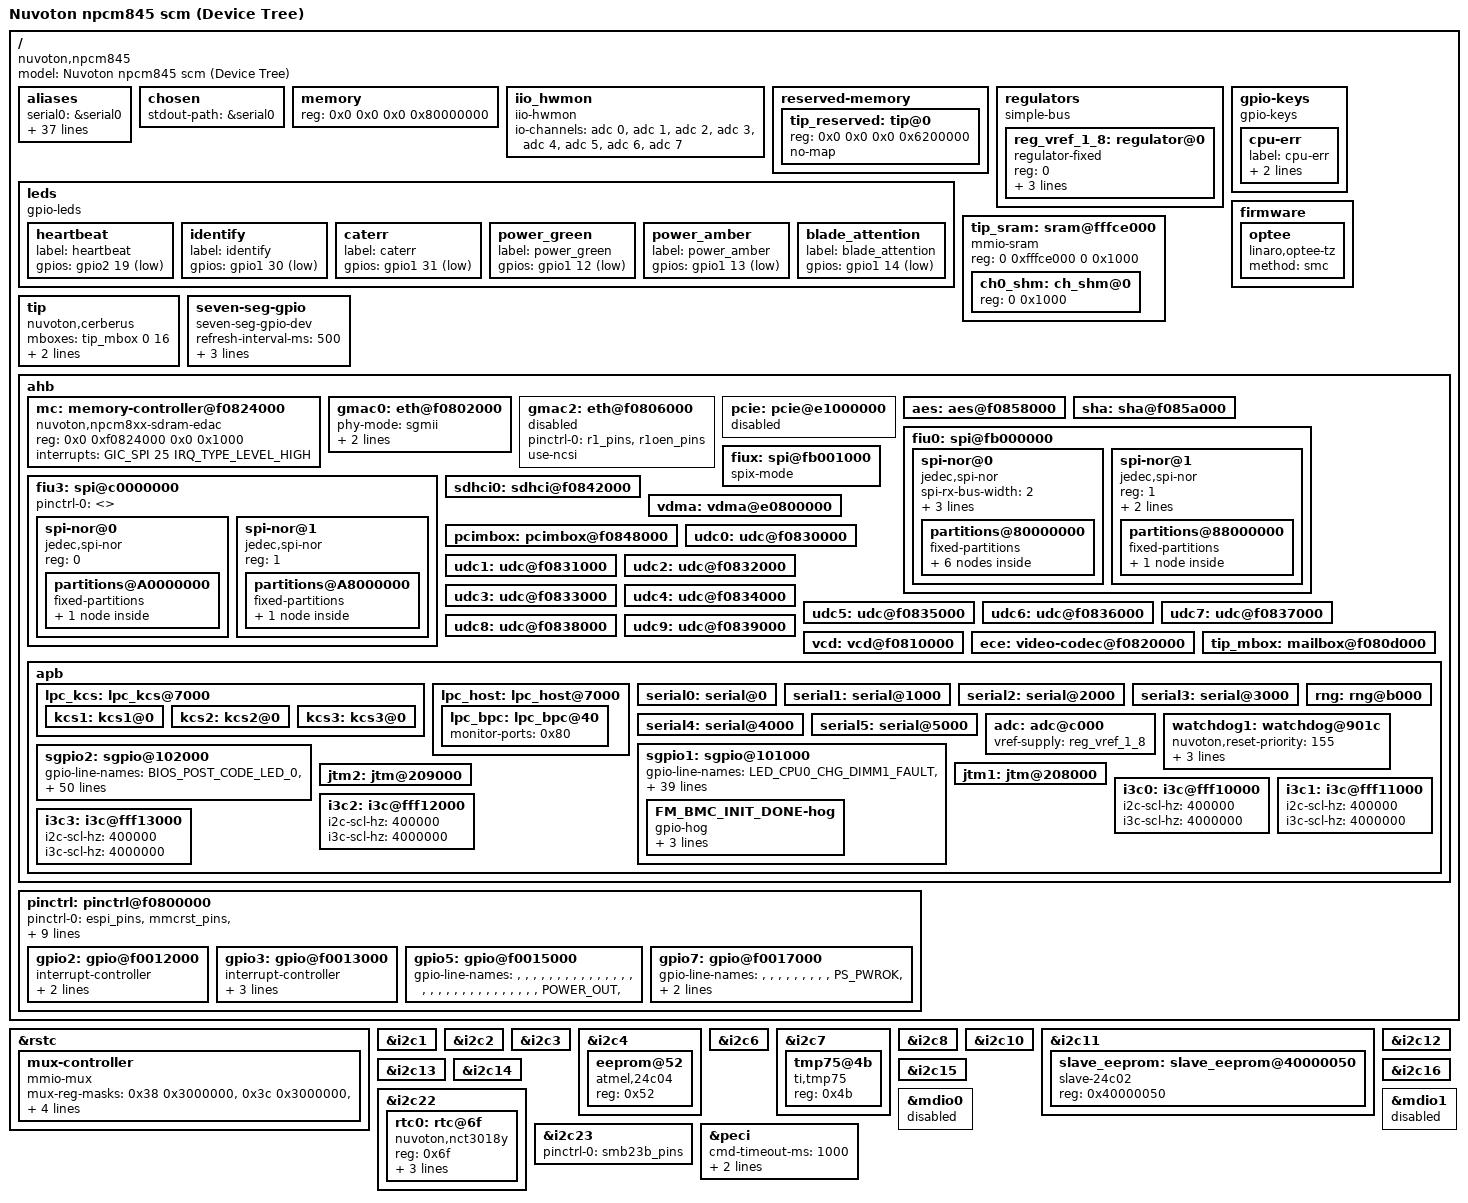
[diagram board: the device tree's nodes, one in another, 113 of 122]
// SPDX-License-Identifier: GPL-2.0
// Copyright (c) 2018 Nuvoton Technology tomer.maimon@nuvoton.com
// Copyright 2018 Google, Inc.

/dts-v1/;
#include "nuvoton-npcm845.dtsi"
#include "nuvoton-npcm845-pincfg-evb.dtsi"
#include <dt-bindings/thermal/thermal.h>

/ {
	model = "Nuvoton npcm845 scm (Device Tree)";
	compatible = "nuvoton,npcm845";

	aliases {
		serial0 = &serial0;
		serial1 = &serial1;
		serial2 = &serial2;
		serial3 = &serial3;
		serial4 = &serial4;
		serial5 = &serial5;
		ethernet0 = &gmac0;
		ethernet1 = &gmac2;
		udc0 = &udc0;
		udc1 = &udc1;
		udc2 = &udc2;
		udc3 = &udc3;
		udc4 = &udc4;
		udc5 = &udc5;
		udc6 = &udc6;
		udc7 = &udc7;
		udc8 = &udc8;
		udc9 = &udc9;
		i2c1 = &i2c1;
		i2c2 = &i2c2;
		i2c3 = &i2c3;
		i2c4 = &i2c4;
		i2c6 = &i2c6;
		i2c7 = &i2c7;
		i2c8 = &i2c8;
		i2c10 = &i2c10;
		i2c12 = &i2c12;
		i2c13 = &i2c13;
		i2c14 = &i2c14;
		i2c15 = &i2c15;
		i2c16 = &i2c23;
		i2c17 = &i2c11;
		i2c22 = &i2c22;
		i2c23 = &i2c16;
		fiu0 = &fiu0;
		fiu1 = &fiu3;
		fiu2 = &fiux;
		fiu3 = &fiu1;
	};

	chosen {
		stdout-path = &serial0;
	};

	memory {
		reg = <0x0 0x0 0x0 0x80000000>;
	};

	iio_hwmon {
		compatible = "iio-hwmon";
		io-channels = <&adc 0>, <&adc 1>, <&adc 2>, <&adc 3>,
			<&adc 4>, <&adc 5>, <&adc 6>, <&adc 7>;
	};

	reserved-memory {
		#address-cells = <2>;
		#size-cells = <2>;
		ranges;

		tip_reserved: tip@0 {
			reg = <0x0 0x0 0x0 0x6200000>;
			no-map;
		};
	};

	regulators {
		compatible = "simple-bus";
		#address-cells = <1>;
		#size-cells = <0>;

		reg_vref_1_8: regulator@0 {
			compatible = "regulator-fixed";
			reg = <0>;
			regulator-name = "vref_1_8v";
			regulator-min-microvolt = <1800000>;
			regulator-max-microvolt = <1800000>;
		};
	};

	leds {
		compatible = "gpio-leds";

		heartbeat {
			label = "heartbeat";
			gpios = <&gpio2 19 GPIO_ACTIVE_LOW>; /* gpio83 */
		};

		identify {
			label = "identify";
			gpios = <&gpio1 30 GPIO_ACTIVE_LOW>; /* gpio62 */
		};

		caterr {
			label = "caterr";
			gpios = <&gpio1 31 GPIO_ACTIVE_LOW>; /* gpio63 */
		};

		power_green {
			label = "power_green";
			gpios = <&gpio1 12 GPIO_ACTIVE_LOW>; /* gpio44 */
		};

		power_amber {
			label = "power_amber";
			gpios = <&gpio1 13 GPIO_ACTIVE_LOW>; /* gpio45 */
		};

		blade_attention {
			label = "blade_attention";
			gpios = <&gpio1 14 GPIO_ACTIVE_LOW>; /* gpio46 */
		};
	};

	gpio-keys {
		compatible = "gpio-keys";
		cpu-err {
			label = "cpu-err";
			gpios = <&sgpio2 34 GPIO_ACTIVE_LOW>;
			linux,code = <34>;
		};
	};

	firmware {
		optee {
			compatible = "linaro,optee-tz";
			method = "smc";
		};
	};

	tip_sram: sram@fffce000 {
		compatible = "mmio-sram";
		reg = <0 0xfffce000 0 0x1000>;
		#address-cells = <1>;
		#size-cells = <1>;
		ranges = <0 0 0xfffce000 0x1000>;
		ch0_shm: ch_shm@0 {
			reg = <0 0x1000>;
		};
	};

	tip {
		compatible = "nuvoton,cerberus";
		mboxes = <&tip_mbox 0 16>; /*channel 0, 16th doorbell */
		mbox-names = "cerberus";
		shmem = <&ch0_shm>;
		status = "okay";
	};

	seven-seg-gpio {
		compatible = "seven-seg-gpio-dev";
		refresh-interval-ms = <500>;
		seven-gpios = <&sgpio2 0 0>,
			      <&sgpio2 1 0>,
			      <&sgpio2 2 0>,
			      <&sgpio2 3 0>,
			      <&sgpio2 4 0>,
			      <&sgpio2 5 0>,
			      <&sgpio2 6 0>,
			      <&sgpio2 7 0>;
		status = "okay";
	};

	ahb {
		mc: memory-controller@f0824000 {
			compatible = "nuvoton,npcm8xx-sdram-edac";
			reg = <0x0 0xf0824000 0x0 0x1000>;
			interrupts = <GIC_SPI 25 IRQ_TYPE_LEVEL_HIGH>;
			status = "okay";
		};


		gmac0: eth@f0802000 {
			phy-mode = "sgmii";
			npcm,sgmii-an;
			snps,eee-force-disable;
			status = "okay";
		};

		gmac2: eth@f0806000 {
			pinctrl-names = "default";
			pinctrl-0 = <&r1_pins
					&r1oen_pins>;

			status = "disabled";
			use-ncsi;
		};

		pcie: pcie@e1000000 {
			status = "disabled";
		};

		aes: aes@f0858000 {
			status = "okay";
		};

		sha: sha@f085a000 {
			status = "okay";
		};

		fiu0: spi@fb000000 {
			status = "okay";
			spi-nor@0 {
				compatible = "jedec,spi-nor";
				#address-cells = <1>;
				#size-cells = <1>;
				spi-rx-bus-width = <2>;
				spi-tx-bus-width = <2>;
				reg = <0>;
				spi-max-frequency = <50000000>;
				partitions@80000000 {
					compatible = "fixed-partitions";
					#address-cells = <1>;
					#size-cells = <1>;
					bmc@0{
						label = "bmc";
						reg = <0x00000000 0x04000000>;
					};
					u-boot@0 {
						label = "u-boot";
						reg = <0x00000000 0x003C0000>;
					};
					u-boot-env@3c0000{
						label = "u-boot-env";
						reg = <0x003C0000 0x00040000>;
					};
					kernel@400000 {
						label = "kernel";
						reg = <0x00400000 0x00800000>;
					};
					rofs@c00000 {
						label = "rofs";
						reg = <0x00C00000 0x03000000>;
					};
					rwfs@3c00000 {
						label = "rwfs";
						reg = <0x3C00000 0x400000>;
					};
				};
			};
			spi-nor@1 {
				compatible = "jedec,spi-nor";
				#address-cells = <1>;
				#size-cells = <1>;
				reg = <1>;
				spi-rx-bus-width = <2>;
				spi-tx-bus-width = <2>;
				partitions@88000000 {
					compatible = "fixed-partitions";
					#address-cells = <1>;
					#size-cells = <1>;
					spare@0 {
						label = "spi0-cs1-spare";
						reg = <0x0 0x04000000>;
					};
				};
			};
		};

		fiu3: spi@c0000000 {
			status = "okay";
			pinctrl-0 = <>;
			spi-nor@0 {
				compatible = "jedec,spi-nor";
				#address-cells = <1>;
				#size-cells = <1>;
				reg = <0>;
				partitions@A0000000 {
					compatible = "fixed-partitions";
					#address-cells = <1>;
					#size-cells = <1>;
					system1@0 {
						label = "image-bios";
						reg = <0x0 0x0>;
					};
				};
			};
			spi-nor@1 {
				compatible = "jedec,spi-nor";
				#address-cells = <1>;
				#size-cells = <1>;
				reg = <1>;
				partitions@A8000000 {
					compatible = "fixed-partitions";
					#address-cells = <1>;
					#size-cells = <1>;
					system1@0 {
						label = "image-bios-1";
						reg = <0x0 0x0>;
					};
				};
			};
		};

		fiux: spi@fb001000 {
			spix-mode;
		};

		sdhci0: sdhci@f0842000 {
			status = "okay";
		};

		vdma: vdma@e0800000 {
			status = "okay";
		};

		pcimbox: pcimbox@f0848000 {
			status = "okay";
		};

		udc0:udc@f0830000 {
			status = "okay";
		};

		udc1:udc@f0831000 {
			status = "okay";
		};

		udc2:udc@f0832000 {
			status = "okay";
		};

		udc3:udc@f0833000 {
			status = "okay";
		};

		udc4:udc@f0834000 {
			status = "okay";
		};

		udc5:udc@f0835000 {
			status = "okay";
		};

		udc6:udc@f0836000 {
			status = "okay";
		};

		udc7:udc@f0837000 {
			status = "okay";
		};

		udc8:udc@f0838000 {
			status = "okay";
		};

		udc9:udc@f0839000 {
			status = "okay";
		};

		vcd: vcd@f0810000 {
			status = "okay";
		};

		ece: video-codec@f0820000 {
			status = "okay";
		};

		tip_mbox: mailbox@f080d000 {
			status = "okay";
		};

		apb {
			lpc_kcs: lpc_kcs@7000 {
				kcs1: kcs1@0 {
					status = "okay";
				};

				kcs2: kcs2@0 {
					status = "okay";
				};

				kcs3: kcs3@0 {
					status = "okay";
				};
			};

			lpc_host: lpc_host@7000 {
				lpc_bpc: lpc_bpc@40 {
					monitor-ports = <0x80>;
					status = "okay";
				};
			};

			serial0: serial@0 {
				status = "okay";
			};

			serial1: serial@1000 {
				status = "okay";
			};

			serial2: serial@2000 {
				status = "okay";
			};

			serial3: serial@3000 {
				status = "okay";
			};

			serial4: serial@4000 {
				status = "okay";
			};

			serial5: serial@5000 {
				status = "okay";
			};

			rng: rng@b000 {
				status = "okay";
			};

			adc: adc@c000 {
				/* enable external vref */
				vref-supply = <&reg_vref_1_8>;
				#io-channel-cells = <1>;
				status = "okay";
			};

			watchdog1: watchdog@901c {
				nuvoton,reset-priority = <155>;
				nuvoton,card-reset-type = "porst";
				nuvoton,ext1-reset-type = "wd1";
				nuvoton,ext2-reset-type = "sw2";
				status = "okay";
			};

			sgpio1: sgpio@101000 {
				status = "okay";
				gpio-line-names =
					/* output pin */
					"LED_CPU0_CHG_DIMM1_FAULT","LED_CPU0_CHG_DIMM2_FAULT","LED_CPU0_CHH_DIMM1_FAULT","LED_CPU0_CHH_DIMM2_FAULT","LED_CPU1_CHG_DIMM1_FAULT","LED_CPU1_CHG_DIMM2_FAULT","LED_CPU1_CHH_DIMM1_FAULT","LED_CPU1_CHH_DIMM2_FAULT",
					"","","","","","","","",
					"LED_CPU0_CHI_DIMM1_FAULT","LED_CPU0_CHI_DIMM2_FAULT","LED_CPU0_CHJ_DIMM1_FAULT","LED_CPU0_CHJ_DIMM2_FAULT","LED_CPU0_CHK_DIMM1_FAULT","LED_CPU0_CHK_DIMM2_FAULT","LED_CPU0_CHL_DIMM1_FAULT","LED_CPU0_CHL_DIMM2_FAULT",
					"LED_CPU1_CHI_DIMM1_FAULT","LED_CPU1_CHI_DIMM2_FAULT","LED_CPU1_CHJ_DIMM1_FAULT","LED_CPU1_CHJ_DIMM2_FAULT","LED_CPU1_CHK_DIMM1_FAULT","LED_CPU1_CHK_DIMM2_FAULT","LED_CPU1_CHL_DIMM1_FAULT","LED_CPU1_CHL_DIMM2_FAULT",
					"SURPRISE_RESET","FM_CPU1_INTR_CLK_CONFDONE","FM_GLOBAL_RESET","FM_BMC_INIT_DONE","IRQ_BMC_CPU_NMI_P0","IRQ_BMC_CPU_NMI_P1","","",
					"","","","","","","","",
					"","","","","","","","",
					"","","","","","","","",
					/* input pin */
					"FM_CPU0_PKGID0","FM_CPU0_PKGID1","FM_CPU0_PKGID2","H_CPU0_MEMTRIP_LVC1_N","FM_CPU1_PKGID0","FM_CPU1_PKGID1","FM_CPU1_PKGID2","H_CPU1_MEMTRIP_LVC1_N",
					"","","","","","","","",
					"FM_BOARD_REV_ID0","FM_BOARD_REV_ID1","FM_BOARD_REV_ID2","FM_BOARD_SKU_ID0","FM_BOARD_SKU_ID1","FM_BOARD_SKU_ID2","FM_BOARD_SKU_ID3","FM_BOARD_SKU_ID4",
					"FM_BOARD_SKU_ID5","FM_VAL_DBG_JUMPER_EN","FM_SERIAL_BOOT","","PWRGD_S0_PWROK_CPU0","","","",
					"","","","FM_1200VA_OC","","","","",
					"","","","","","","","",
					"","","","","","","","",
					"","","","","","","","";

				FM_BMC_INIT_DONE-hog {
					gpio-hog;
					gpios = <35 GPIO_ACTIVE_HIGH>;
					output-high;
					line-name = "FM_BMC_INIT_DONE";
				};
			};

			sgpio2: sgpio@102000 {
				status = "okay";
				gpio-line-names =
					/* output pin */
					"BIOS_POST_CODE_LED_0","BIOS_POST_CODE_LED_1","BIOS_POST_CODE_LED_2","BIOS_POST_CODE_LED_3","BIOS_POST_CODE_LED_4","BIOS_POST_CODE_LED_5","BIOS_POST_CODE_LED_6","BIOS_POST_CODE_LED_7",
					"LED_CPU0_CHA_DIMM1_FAULT","LED_CPU0_CHA_DIMM2_FAULT","LED_CPU0_CHB_DIMM1_FAULT","LED_CPU0_CHB_DIMM2_FAULT","LED_CPU0_CHC_DIMM1_FAULT","LED_CPU0_CHC_DIMM2_FAULT","LED_CPU0_CHD_DIMM1_FAULT","LED_CPU0_CHD_DIMM2_FAULT",
					"LED_CPU0_CHE_DIMM1_FAULT","LED_CPU0_CHE_DIMM2_FAULT","LED_CPU0_CHF_DIMM1_FAULT","LED_CPU0_CHF_DIMM2_FAULT","","","","",
					"","","","","LED_CPU1_CHA_DIMM1_FAULT","LED_CPU1_CHA_DIMM2_FAULT","LED_CPU1_CHB_DIMM1_FAULT","LED_CPU1_CHB_DIMM2_FAULT",
					"LED_CPU1_CHC_DIMM1_FAULT","LED_CPU1_CHC_DIMM2_FAULT","LED_CPU1_CHD_DIMM1_FAULT","LED_CPU1_CHD_DIMM2_FAULT","LED_CPU1_CHE_DIMM1_FAULT","LED_CPU1_CHE_DIMM2_FAULT","LED_CPU1_CHF_DIMM1_FAULT","LED_CPU1_CHF_DIMM2_FAULT",
					"","","","","","","","",
					"","","","","","","","",
					"","","","","","","","",
					/* input pin */
					"FM_CPU0_SKTOCC_LVT3_PLD_N","H_CPU0_THERMTRIP_LVC1_N","IRQ_CPU0_VRHOT_N","H_CPU0_MON_FAIL_PLD_LVC1_N","IRQ_CPU0_MEM_VRHOT_N","H_CPU0_MEMHOT_OUT_LVC1_N","FM_CPU0_PROC_ID0","FM_CPU0_PROC_ID1",
					"CPU_MISMATCH","","FM_CPU1_SKTOCC_LVT3_PLD_N","H_CPU1_THERMTRIP_LVC1_N","IRQ_CPU1_VRHOT_N","H_CPU1_MON_FAIL_PLD_LVC1_N","IRQ_CPU1_MEM_VRHOT_N","H_CPU1_MEMHOT_OUT_LVC1_N",
					"FM_CPU1_PROC_ID0","FM_CPU1_PROC_ID1","CPU_MISMATCH","","","","","",
					"","","","","","","","",
					"","","","","","","","FM_S3M_CPU0_CPLD_CRC_ERROR",
					"FM_S3M_CPU1_CPLD_CRC_ERROR","H_CPU0_CATERR_LVC1_ENCODE[1]","H_CPU0_CATERR_LVC1_ENCODE[0]","H_CPU1_CATERR_LVC1_ENCODE[1]","H_CPU1_CATERR_LVC1_ENCODE[0]","","","",
					"","","","","","","","",
					"","MEM_PWR_FLT","CPU_PWR_FLT","P3V3_FAULT","PSU_PWR_FLT","","","CPU_AUX_PWR_FLT";
			};

			jtm1: jtm@208000 {
				status = "okay";
			};

			jtm2: jtm@209000 {
				status = "okay";
			};

			i3c0: i3c@fff10000 {
				status = "okay";
				i2c-scl-hz = <400000>;
				i3c-scl-hz = <4000000>;
			};

			i3c1: i3c@fff11000 {
				status = "okay";
				i2c-scl-hz = <400000>;
				i3c-scl-hz = <4000000>;
			};

			i3c2: i3c@fff12000 {
				status = "okay";
				i2c-scl-hz = <400000>;
				i3c-scl-hz = <4000000>;
			};

			i3c3: i3c@fff13000 {
				status = "okay";
				i2c-scl-hz = <400000>;
				i3c-scl-hz = <4000000>;
			};
		};
	};

 	pinctrl: pinctrl@f0800000 {
		pinctrl-names = "default";
		pinctrl-0 = <
				&espi_pins
				&mmcrst_pins
				&pin240_slew
				&pin241_slew
				&pin242_slew
				&pin243_slew
				&pin244_slew
				&pin245_slew
				&pin246_slew
				&pin247_slew
				&pin4_slew
				&pin5_slew
				&pin6_slew
				&pin7_slew
				&spix_pins
				&pin110_slew
				&pin111_slew
				&pin112_slew
				&pin113_slew
				&pin208_slew
				&pin209_slew
				&pin210_slew
				&pin211_slew
				&pin212_slew
				&pin213_slew
				&pin214_slew
				&pin215_slew
				&pin216_slew
				&pin217_slew
				&pin250_slew>;

		gpio2: gpio@f0012000 {
			/* P3V_BAT_EN=gpio83 */
			interrupt-controller;
			#interrupt-cells = <2>;
			gpio-line-names =
			/*64-95*/
			"","","","","","","","",
			"","","","","","","","",
			"","","","P3V_BAT_EN","","","","",
			"","","","","","","","";
		};

		gpio3: gpio@f0013000 {
			/* NMI_BUTTON=gpio96 */
			interrupt-controller;
			#interrupt-cells = <2>;
			gpio-line-names =
			/*96-127*/
			"NMI_BUTTON","","","","","","","",
			"","","","","","","","",
			"","","DP_INTP_3V3_R","RST_DP_N","","","","",
			"","","","","","","","";
		};
		gpio5: gpio@f0015000 {
			/* POWER_OUT=gpio190 */
			gpio-line-names =
			/*160-191*/
			"","","","","","","","",
			"","","","","","","","",
			"","","","","","","","",
			"","","","","","","POWER_OUT","";
		};
		gpio7: gpio@f0017000 {
			/* PS_PWROK=gpio233, RESET_BUTTON=gpio234, RESET_OUT=gpio235 */
			gpio-line-names =
			/*224-255*/
			"","","","","","","","",
			"","PS_PWROK","RESET_BUTTON","RESET_OUT","","","","",
			"","","","","","","","",
			"","","","","","","","";
		};
	};
};

&rstc {
	mux-controller {
		compatible = "mmio-mux";
		#mux-control-cells = <1>;

		/* Clean SIOX1/2 reset bits of WD0RCR/WD1RCR/WD2RCR/SWRSTC1/SWRSTC2/SWRSTC3/CORSTC/TIPRSTC */
		mux-reg-masks = <0x38 0x3000000>, <0x3c 0x3000000>, <0x40 0x3000000>,
				<0x44 0x3000000>, <0x48 0x3000000>, <0x4c 0x3000000>,
				<0x5c 0x3000000>, <0x50 0x3000000>;
		idle-states = <0>, <0>, <0>,
			      <0>, <0>, <0>,
			      <0>, <0>;
	};
};

&i2c1 {
	status = "okay";
};

&i2c2 {
	status = "okay";
};

&i2c3 {
	status = "okay";
};

&i2c4 {
	status = "okay";

	eeprom@52 {
		compatible = "atmel,24c04";
		reg = <0x52>;
	};
};

&i2c6 {
	status = "okay";
};

&i2c7 {
	status = "okay";

	tmp75@4b {
		compatible = "ti,tmp75";
		reg = <0x4b>;
	};
};

&i2c8 {
	status = "okay";
};

&i2c10 {
	status = "okay";
};

&i2c11 {
	status = "okay";
	slave_eeprom: slave_eeprom@40000050 {
		compatible = "slave-24c02";
		reg = <0x40000050>;
		status = "okay";
	};
};

&i2c12 {
	status = "okay";
};

&i2c13 {
	status = "okay";
};

&i2c14 {
	status = "okay";
};

&i2c15 {
	status = "okay";
};

&i2c16 {
	status = "okay";
};

&i2c22 {
	status = "okay";

	rtc0: rtc@6f {
		compatible = "nuvoton,nct3018y";
		reg = <0x6f>;
		#clock-cells = <0>;

		interrupt-parent = <&gpio2>;
		interrupts = <5 IRQ_TYPE_EDGE_FALLING>; /* gpio 37 */
		interrupt-names = "irq";
		wakeup-source;
	};
};

&i2c23 {
	pinctrl-0 = <&smb23b_pins>;
	status = "okay";
};

&mdio0 {
	status = "disabled";
};

&mdio1 {
	status = "disabled";
};

&peci {
	cmd-timeout-ms = <1000>;
	npcm,pull-down = <0>;
	npcm,host-neg-bit-rate = <15>;
	#address-cells = <1>;
	#size-cells = <0>;
	status = "okay";
};
